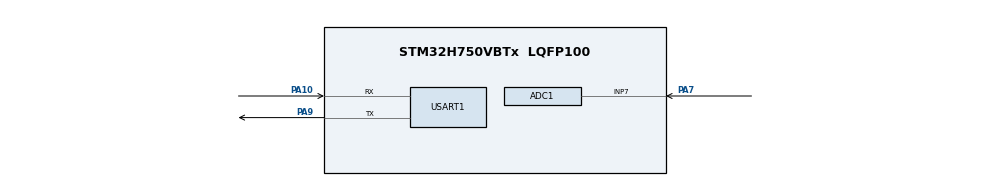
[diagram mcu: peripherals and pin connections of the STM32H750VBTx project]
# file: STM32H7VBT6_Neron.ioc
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ADC1.Channel-0\#ChannelRegularConversion=ADC_CHANNEL_7
ADC1.ClockPrescaler=ADC_CLOCK_ASYNC_DIV2
ADC1.ConversionDataManagement=ADC_CONVERSIONDATA_DMA_CIRCULAR
ADC1.ExternalTrigConv=ADC_EXTERNALTRIG_T3_TRGO
ADC1.NbrOfConversionFlag=1
ADC1.OffsetNumber-0\#ChannelRegularConversion=ADC_OFFSET_NONE
ADC1.OffsetSignedSaturation-0\#ChannelRegularConversion=DISABLE
ADC1.Rank-0\#ChannelRegularConversion=1
ADC1.Resolution=ADC_RESOLUTION_12B
ADC1.SamplingTime-0\#ChannelRegularConversion=ADC_SAMPLETIME_1CYCLE_5
ADC1.master=1
CORTEX_M7.CPU_DCache=Enabled
CORTEX_M7.CPU_ICache=Enabled
CORTEX_M7.default_mode_Activation=1
Dma.ADC1.0.Direction=DMA_PERIPH_TO_MEMORY
Dma.ADC1.0.EventEnable=DISABLE
Dma.ADC1.0.FIFOMode=DMA_FIFOMODE_DISABLE
Dma.ADC1.0.Instance=DMA1_Stream0
Dma.ADC1.0.MemDataAlignment=DMA_MDATAALIGN_HALFWORD
Dma.ADC1.0.MemInc=DMA_MINC_ENABLE
Dma.ADC1.0.Mode=DMA_CIRCULAR
Dma.ADC1.0.PeriphDataAlignment=DMA_PDATAALIGN_HALFWORD
Dma.ADC1.0.PeriphInc=DMA_PINC_DISABLE
Dma.ADC1.0.Polarity=HAL_DMAMUX_REQ_GEN_RISING
Dma.ADC1.0.Priority=DMA_PRIORITY_HIGH
Dma.ADC1.0.RequestNumber=1
Dma.ADC1.0.SignalID=NONE
Dma.ADC1.0.SyncEnable=DISABLE
Dma.ADC1.0.SyncPolarity=HAL_DMAMUX_SYNC_NO_EVENT
Dma.ADC1.0.SyncRequestNumber=1
Dma.ADC1.0.SyncSignalID=NONE
Dma.Request0=ADC1
Mcu.Family=STM32H7
Mcu.Name=STM32H750VBTx
Mcu.Package=LQFP100
NVIC.DMA1_Stream0_IRQn=true\:0\:0\:false\:false\:true\:false\:true\:true
NVIC.PriorityGroup=NVIC_PRIORITYGROUP_4
PA10.Mode=Asynchronous
PA10.Signal=USART1_RX
PA7.Signal=ADCx_INP7
PA9.Mode=Asynchronous
PA9.Signal=USART1_TX
PH0-OSC_IN\ (PH0).Mode=HSE-External-Clock-Source
PH0-OSC_IN\ (PH0).Signal=RCC_OSC_IN
ProjectManager.HeapSize=0x4000
ProjectManager.StackSize=0x4000
ProjectManager.TargetToolchain=MDK-ARM V5.32
RCC.ADCFreq_Value=100000000
RCC.APB1Freq_Value=120000000
RCC.APB2Freq_Value=120000000
RCC.APB3Freq_Value=120000000
RCC.APB4Freq_Value=120000000
RCC.CortexFreq_Value=480000000
RCC.D1PPRE=RCC_APB3_DIV2
RCC.D2PPRE1=RCC_APB1_DIV2
RCC.D2PPRE2=RCC_APB2_DIV2
RCC.D3PPRE=RCC_APB4_DIV2
RCC.DIVM1=4
RCC.DIVM2=4
RCC.DIVN1=60
RCC.DIVN2=25
RCC.DIVP2=4
RCC.HCLKFreq_Value=240000000
RCC.HPRE=RCC_HCLK_DIV2
RCC.HSE_VALUE=8000000
RCC.PLL2FRACN=0
RCC.PLL3FRACN=0
RCC.PLLFRACN=0
RCC.SYSCLKFreq_VALUE=480000000
RCC.SYSCLKSource=RCC_SYSCLKSOURCE_PLLCLK
RCC.USBFreq_Value=480000000
SH.ADCx_INP7.0=ADC1_INP7,IN7-Single-Ended
STMicroelectronics.X-CUBE-AI.10.1.0.ActivationBufferSizeList=7136
STMicroelectronics.X-CUBE-AI.10.1.0.ActivationBuffers=pool0
STMicroelectronics.X-CUBE-AI.10.1.0.ActivationNames=pool0
STMicroelectronics.X-CUBE-AI.10.1.0.ActivationSizes=AI_NETWORK_DATA_ACTIVATION_1_SIZE
STMicroelectronics.X-CUBE-AI.10.1.0.ApplicationCcDeviceJjApplication=ApplicationTemplate
STMicroelectronics.X-CUBE-AI.10.1.0.HeapSize=0x4000
STMicroelectronics.X-CUBE-AI.10.1.0.InternalRamActivationBufferMaxSize=AI_NETWORK_DATA_ACTIVATIONS_SIZE
STMicroelectronics.X-CUBE-AI.10.1.0.LatestDirectoryUsed-d44da2aed7d606475b1713c8edc45d25b0a35dfb31f6b0cad93158b70a8a74bb=E\:\\VisierWorkSpace\\ElectricDesign\\STM32-Wave-Recognition\\Model
STMicroelectronics.X-CUBE-AI.10.1.0.MaximumNumberOfInputLayer=1
STMicroelectronics.X-CUBE-AI.10.1.0.MaximumNumberOfOutputLayer=1
STMicroelectronics.X-CUBE-AI.10.1.0.MaximumSizeOfInputLayer=1
STMicroelectronics.X-CUBE-AI.10.1.0.MaximumSizeOfOutputLayer=1
STMicroelectronics.X-CUBE-AI.10.1.0.ModelActualCompression-d44da2aed7d606475b1713c8edc45d25b0a35dfb31f6b0cad93158b70a8a74bb=0.0
STMicroelectronics.X-CUBE-AI.10.1.0.ModelCompression-d44da2aed7d606475b1713c8edc45d25b0a35dfb31f6b0cad93158b70a8a74bb=None
STMicroelectronics.X-CUBE-AI.10.1.0.ModelFlashOccupation-d44da2aed7d606475b1713c8edc45d25b0a35dfb31f6b0cad93158b70a8a74bb=81932
STMicroelectronics.X-CUBE-AI.10.1.0.ModelHashList=d44da2aed7d606475b1713c8edc45d25b0a35dfb31f6b0cad93158b70a8a74bb
STMicroelectronics.X-CUBE-AI.10.1.0.ModelKind-d44da2aed7d606475b1713c8edc45d25b0a35dfb31f6b0cad93158b70a8a74bb=KERAS
STMicroelectronics.X-CUBE-AI.10.1.0.ModelMacc-d44da2aed7d606475b1713c8edc45d25b0a35dfb31f6b0cad93158b70a8a74bb=111896
STMicroelectronics.X-CUBE-AI.10.1.0.ModelName-d44da2aed7d606475b1713c8edc45d25b0a35dfb31f6b0cad93158b70a8a74bb=network
STMicroelectronics.X-CUBE-AI.10.1.0.ModelNameList=network
STMicroelectronics.X-CUBE-AI.10.1.0.ModelRamOccupation-d44da2aed7d606475b1713c8edc45d25b0a35dfb31f6b0cad93158b70a8a74bb=7136
STMicroelectronics.X-CUBE-AI.10.1.0.ModelStructureFile-d44da2aed7d606475b1713c8edc45d25b0a35dfb31f6b0cad93158b70a8a74bb=E\:\\VisierWorkSpace\\ElectricDesign\\STM32-Wave-Recognition\\Model\\waveform_cnn_256.h5
STMicroelectronics.X-CUBE-AI.10.1.0.ModelType-d44da2aed7d606475b1713c8edc45d25b0a35dfb31f6b0cad93158b70a8a74bb=STM32Cube.AI MCU runtime
STMicroelectronics.X-CUBE-AI.10.1.0.ReadyForCodeGeneration=true
STMicroelectronics.X-CUBE-AI.10.1.0.StackSize=0x4000
STMicroelectronics.X-CUBE-AI.10.1.0.ValidationInputFile-d44da2aed7d606475b1713c8edc45d25b0a35dfb31f6b0cad93158b70a8a74bb=E\:\\VisierWorkSpace\\ElectricDesign\\STM32\\Scripts\\waveform_dataset_cubeai_input.npy
STMicroelectronics.X-CUBE-AI.10.1.0.ValidationOutputFile-d44da2aed7d606475b1713c8edc45d25b0a35dfb31f6b0cad93158b70a8a74bb=E\:\\VisierWorkSpace\\ElectricDesign\\STM32\\Scripts\\waveform_dataset_cubeai_output.npy
STMicroelectronics.X-CUBE-AI.10.1.0.WorkingBufferStartAddrList=0xFFFFFFFF
STMicroelectronics.X-CUBE-AI.10.1.0.XAaCUBEAaAICcArtificialOoIntelligenceJjCore=true
STMicroelectronics.X-CUBE-AI.10.1.0.copyWeightToRam=false
STMicroelectronics.X-CUBE-AI.10.1.0.copyWeightToRam-d44da2aed7d606475b1713c8edc45d25b0a35dfb31f6b0cad93158b70a8a74bb=false
STMicroelectronics.X-CUBE-AI.10.1.0.customLayerConfigEnabled=false
STMicroelectronics.X-CUBE-AI.10.1.0.customLayerConfigEnabled-d44da2aed7d606475b1713c8edc45d25b0a35dfb31f6b0cad93158b70a8a74bb=false
STMicroelectronics.X-CUBE-AI.10.1.0.noOnnxIoTranspose=false
STMicroelectronics.X-CUBE-AI.10.1.0.noOnnxIoTranspose-d44da2aed7d606475b1713c8edc45d25b0a35dfb31f6b0cad93158b70a8a74bb=false
STMicroelectronics.X-CUBE-AI.10.1.0.useInputAllocation=true
STMicroelectronics.X-CUBE-AI.10.1.0.useInputAllocation-d44da2aed7d606475b1713c8edc45d25b0a35dfb31f6b0cad93158b70a8a74bb=true
STMicroelectronics.X-CUBE-AI.10.1.0.useOutputAllocation=true
STMicroelectronics.X-CUBE-AI.10.1.0.useOutputAllocation-d44da2aed7d606475b1713c8edc45d25b0a35dfb31f6b0cad93158b70a8a74bb=true
TIM3.Period=239
TIM3.TIM_MasterOutputTrigger=TIM_TRGO_UPDATE
USART1.VirtualMode-Asynchronous=VM_ASYNC
VP_MEMORYMAP_VS_MEMORYMAP.Mode=CurAppReg
VP_STMicroelectronics.X-CUBE-AI_VS_ArtificialOoIntelligenceJjXAaCUBEAaAI_10.1.0.Mode=ArtificialOoIntelligenceJjXAaCUBEAaAI
VP_STMicroelectronics.X-CUBE-AI_VS_DeviceJjApplication_10.1.0.Mode=DeviceJjApplication
VP_TIM3_VS_ClockSourceINT.Mode=Internal
board=custom

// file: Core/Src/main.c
/* USER CODE BEGIN Header */
/**
  ******************************************************************************
  * @file           : main.c
  * @brief          : Main program body
  ******************************************************************************
  * @attention
  *
  * Copyright (c) 2025 STMicroelectronics.
  * All rights reserved.
  *
  * This software is licensed under terms that can be found in the LICENSE file
  * in the root directory of this software component.
  * If no LICENSE file comes with this software, it is provided AS-IS.
  *
  ******************************************************************************
  */
/* USER CODE END Header */
#include "main.h"
#include "adc.h"
#include "dma.h"
#include "memorymap.h"
#include "tim.h"
#include "usart.h"
#include "gpio.h"
#include "app_x-cube-ai.h"

/* USER CODE BEGIN Includes */
#include "cube_ai.h"
/* USER CODE END Includes */

/* USER CODE BEGIN PV */
extern UART_HandleTypeDef huart1;
uint8_t Buffer[1];
/* USER CODE END PV */

void SystemClock_Config(void);
static void MPU_Config(void);

/* USER CODE BEGIN 0 */
int fputc(int ch, FILE *f)
{
  HAL_UART_Transmit(&huart1, (uint8_t *)&ch, 1, 0xffff);
  return ch;
}

int fgetc(FILE *f)
{
  uint8_t ch = 0;
  HAL_UART_Receive(&huart1, &ch, 1, 0xffff);
  return ch;
}

void HAL_UART_RxCpltCallback(UART_HandleTypeDef *huart)
{
  if (huart->Instance == USART1)
  {
    HAL_UART_Receive_IT(&huart1, (uint8_t *)Buffer, 1);
  }
}
/* USER CODE END 0 */

int main(void)
{

  /* MPU Configuration--------------------------------------------------------*/
  MPU_Config();

  /* Enable the CPU Cache */

  /* Enable I-Cache---------------------------------------------------------*/
  SCB_EnableICache();

  /* Enable D-Cache---------------------------------------------------------*/
  SCB_EnableDCache();

  /* MCU Configuration--------------------------------------------------------*/

  /* Reset of all peripherals, Initializes the Flash interface and the Systick. */
  HAL_Init();

  /* Configure the system clock */
  SystemClock_Config();

  /* Initialize all configured peripherals */
  MX_GPIO_Init();
  MX_DMA_Init();
  MX_ADC1_Init();
  MX_TIM3_Init();
  MX_USART1_UART_Init();
  MX_X_CUBE_AI_Init();
  /* USER CODE BEGIN 2 */
  HAL_UART_Receive_IT(&huart1, (uint8_t *)Buffer, 1);
  /* USER CODE END 2 */

  /* Infinite loop */
  while (1)
  {

  MX_X_CUBE_AI_Process();
  }
}

void SystemClock_Config(void)
{
  RCC_OscInitTypeDef RCC_OscInitStruct = {0};
  RCC_ClkInitTypeDef RCC_ClkInitStruct = {0};

  /** Supply configuration update enable
  */
  HAL_PWREx_ConfigSupply(PWR_LDO_SUPPLY);

  /** Configure the main internal regulator output voltage
  */
  __HAL_PWR_VOLTAGESCALING_CONFIG(PWR_REGULATOR_VOLTAGE_SCALE1);

  while(!__HAL_PWR_GET_FLAG(PWR_FLAG_VOSRDY)) {}

  __HAL_RCC_SYSCFG_CLK_ENABLE();
  __HAL_PWR_VOLTAGESCALING_CONFIG(PWR_REGULATOR_VOLTAGE_SCALE0);

  while(!__HAL_PWR_GET_FLAG(PWR_FLAG_VOSRDY)) {}

  /** Initializes the RCC Oscillators according to the specified parameters
  * in the RCC_OscInitTypeDef structure.
  */
  RCC_OscInitStruct.OscillatorType = RCC_OSCILLATORTYPE_HSI;
  RCC_OscInitStruct.HSIState = RCC_HSI_DIV1;
  RCC_OscInitStruct.HSICalibrationValue = RCC_HSICALIBRATION_DEFAULT;
  RCC_OscInitStruct.PLL.PLLState = RCC_PLL_ON;
  RCC_OscInitStruct.PLL.PLLSource = RCC_PLLSOURCE_HSI;
  RCC_OscInitStruct.PLL.PLLM = 4;
  RCC_OscInitStruct.PLL.PLLN = 60;
  RCC_OscInitStruct.PLL.PLLP = 2;
  RCC_OscInitStruct.PLL.PLLQ = 2;
  RCC_OscInitStruct.PLL.PLLR = 2;
  RCC_OscInitStruct.PLL.PLLRGE = RCC_PLL1VCIRANGE_3;
  RCC_OscInitStruct.PLL.PLLVCOSEL = RCC_PLL1VCOWIDE;
  RCC_OscInitStruct.PLL.PLLFRACN = 0;
  if (HAL_RCC_OscConfig(&RCC_OscInitStruct) != HAL_OK)
  {
    Error_Handler();
  }

  /** Initializes the CPU, AHB and APB buses clocks
  */
  RCC_ClkInitStruct.ClockType = RCC_CLOCKTYPE_HCLK|RCC_CLOCKTYPE_SYSCLK
                              |RCC_CLOCKTYPE_PCLK1|RCC_CLOCKTYPE_PCLK2
                              |RCC_CLOCKTYPE_D3PCLK1|RCC_CLOCKTYPE_D1PCLK1;
  RCC_ClkInitStruct.SYSCLKSource = RCC_SYSCLKSOURCE_PLLCLK;
  RCC_ClkInitStruct.SYSCLKDivider = RCC_SYSCLK_DIV1;
  RCC_ClkInitStruct.AHBCLKDivider = RCC_HCLK_DIV2;
  RCC_ClkInitStruct.APB3CLKDivider = RCC_APB3_DIV2;
  RCC_ClkInitStruct.APB1CLKDivider = RCC_APB1_DIV2;
  RCC_ClkInitStruct.APB2CLKDivider = RCC_APB2_DIV2;
  RCC_ClkInitStruct.APB4CLKDivider = RCC_APB4_DIV2;

  if (HAL_RCC_ClockConfig(&RCC_ClkInitStruct, FLASH_LATENCY_4) != HAL_OK)
  {
    Error_Handler();
  }
}

 /* MPU Configuration */

void MPU_Config(void)
{
  MPU_Region_InitTypeDef MPU_InitStruct = {0};

  /* Disables the MPU */
  HAL_MPU_Disable();

  /** Initializes and configures the Region and the memory to be protected
  */
  MPU_InitStruct.Enable = MPU_REGION_ENABLE;
  MPU_InitStruct.Number = MPU_REGION_NUMBER0;
  MPU_InitStruct.BaseAddress = 0x0;
  MPU_InitStruct.Size = MPU_REGION_SIZE_4GB;
  MPU_InitStruct.SubRegionDisable = 0x87;
  MPU_InitStruct.TypeExtField = MPU_TEX_LEVEL0;
  MPU_InitStruct.AccessPermission = MPU_REGION_NO_ACCESS;
  MPU_InitStruct.DisableExec = MPU_INSTRUCTION_ACCESS_DISABLE;
  MPU_InitStruct.IsShareable = MPU_ACCESS_SHAREABLE;
  MPU_InitStruct.IsCacheable = MPU_ACCESS_NOT_CACHEABLE;
  MPU_InitStruct.IsBufferable = MPU_ACCESS_NOT_BUFFERABLE;

  HAL_MPU_ConfigRegion(&MPU_InitStruct);
  /* Enables the MPU */
  HAL_MPU_Enable(MPU_PRIVILEGED_DEFAULT);

}

void Error_Handler(void)
{
  __disable_irq();
  while (1)
  {
  }
}
